# C6424_cslr_vpbe_001 register map
Vendor: Texas Instruments
Peripheral module from a debugger description file.
Registers are 32-bit, access not given, reset 0xBE0400 unless marked. A register's access mark holds for its fields unless they carry their own. Offsets are as the file gives them; lines under a group give offsets from that group; [hi:lo] are bit positions; {n}, {i} and the like mark numbered series; 'fields as' and 'values as' point back to an identical list; <NAME> marks a mode.

## VPBE — Video Processor Back End - top-level registers (spec version: 1.00.w.07)
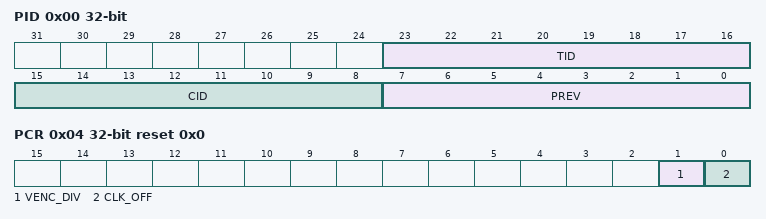
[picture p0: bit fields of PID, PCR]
0x00 PID — Peripheral Revision and Class Information
  [23:16] TID ro — Peripheral Identification VPBE module
  [15:8] CID ro — Class Identification
  [7:0] PREV ro — Peripheral Revision Number Initial Revision
0x04 PCR reset 0x0 — Peripheral Control Register
  [1] VENC_DIV rw — Select Divide by 2 clock for VENC 0: Don't divide by 2 1: Use 1/2 VENC clock
    0=FULL (Use Video Encoder Clock selected in SYSTEM module); 1=HALF (Use 1/2 Video Encoder Clock selected in SYSTEM module)
  [0] CLK_OFF rw — Gate VPBE clocks Only set this bit to 1 when the VPBE is not operational. Clear this bit to 0 prior to any other operations on the VPBE (including writing to other registers).
    0=ON (Normal Operation (Clocks on)); 1=OFF (Clocks Disabled)
